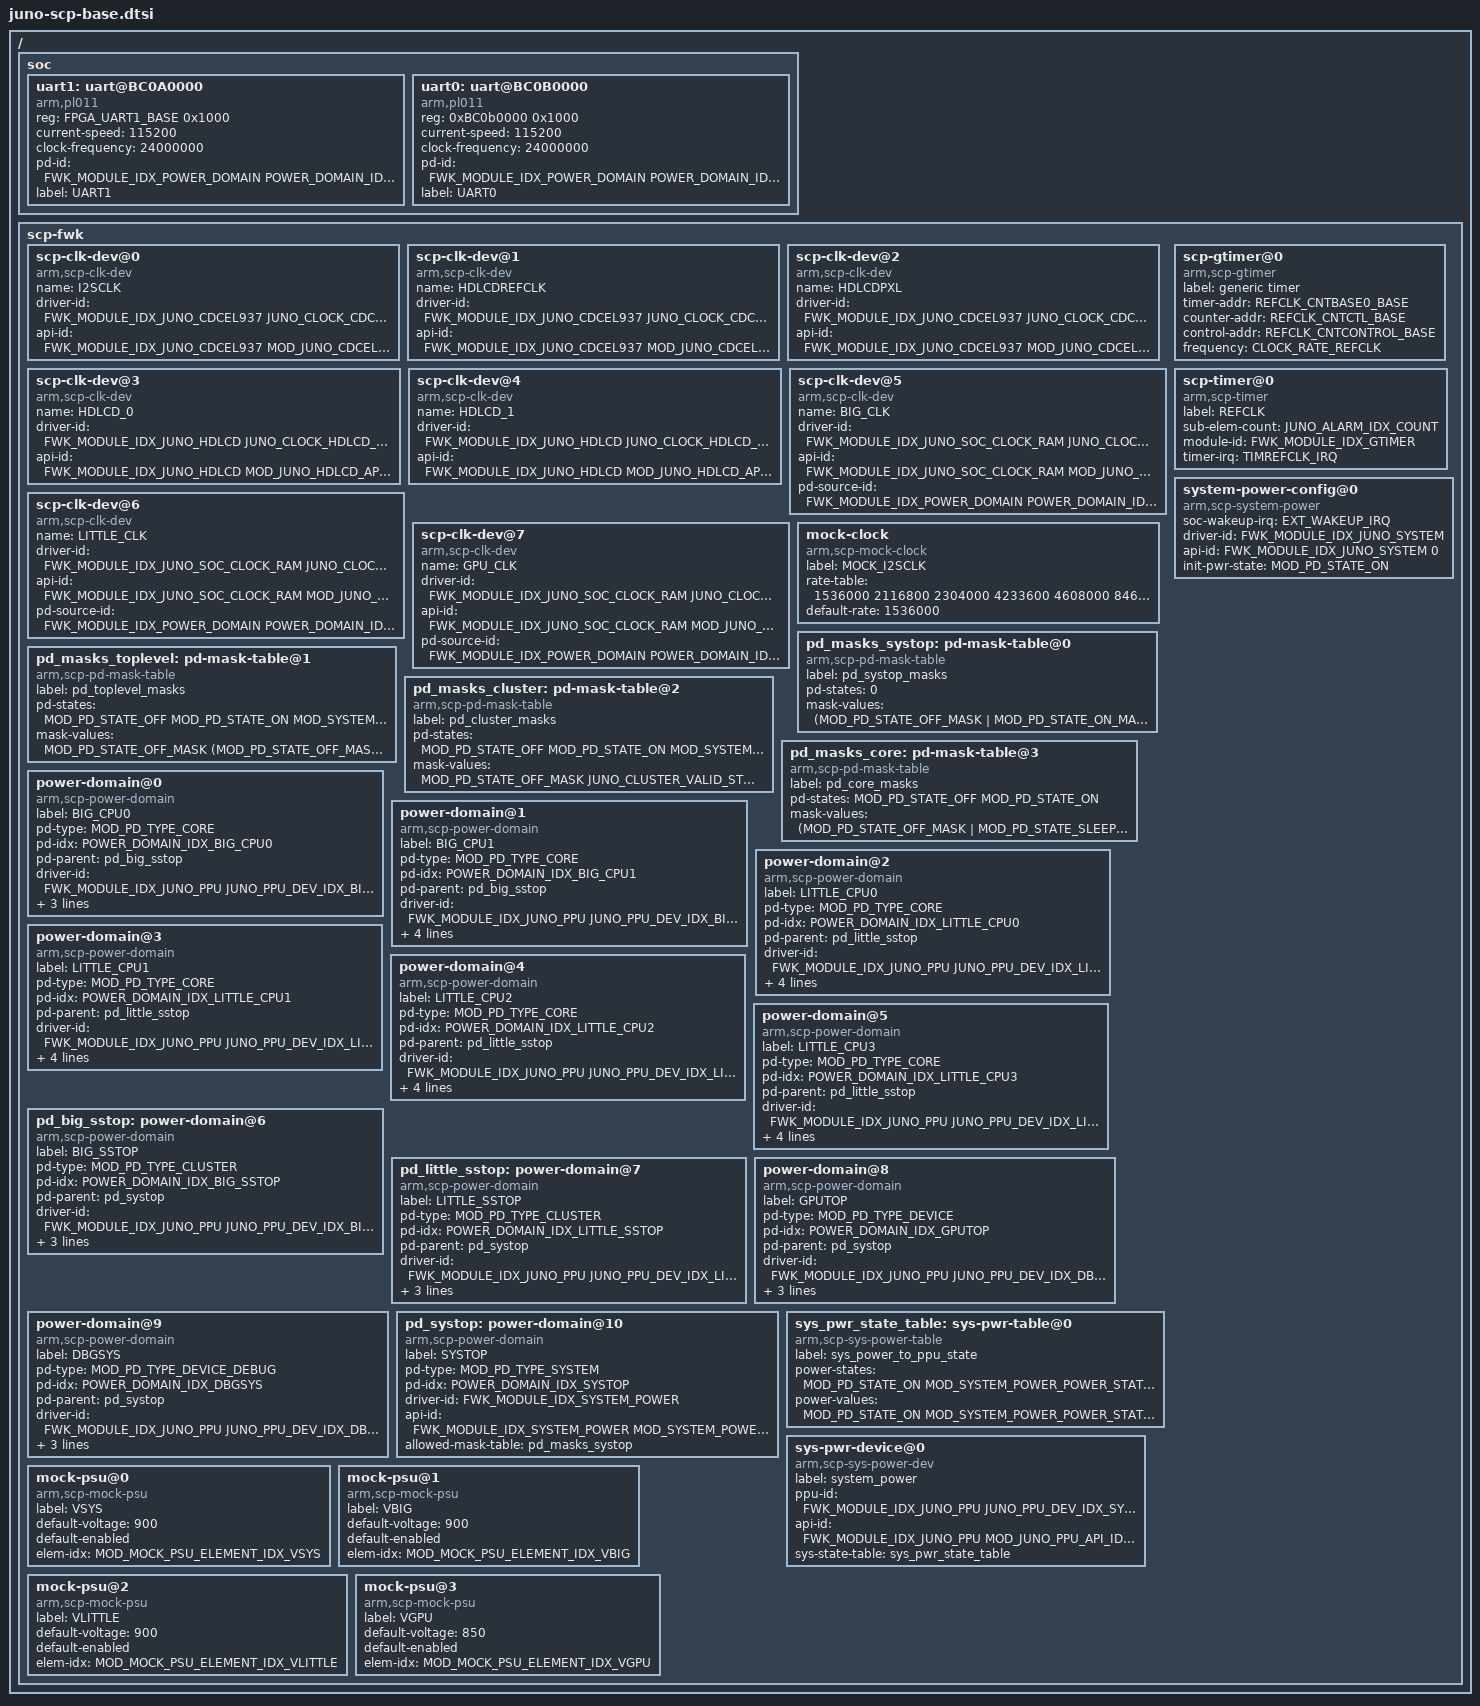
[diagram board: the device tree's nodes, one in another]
/*
 * Arm SCP/MCP Software
 * Copyright (c) 2021, Arm Limited and Contributors. All rights reserved.
 *
 * SPDX-License-Identifier: BSD-3-Clause
 */

/* base SCP .dtsi file for juno boards */

#include "fwk_dt_bindings.h"
#include "juno_dt_bindings.h"

/* must be first include */
#include "base.dtsi"



/ {
    soc {
	    #address-cells = <1>;
	    #size-cells = <1>;

        /* main console uart */
       	uart1: uart@BC0A0000 {
        	compatible = "arm,pl011";
			reg = <FPGA_UART1_BASE 0x1000>;
            current-speed = <115200>;
            clock-frequency = <24000000>;
            pd-id = <FWK_MODULE_IDX_POWER_DOMAIN POWER_DOMAIN_IDX_SYSTOP>;
/*			clocks = <&uartclk>;*/
/*			interrupts = <7 3>; */
/*			interrupt-names = "rx"; */
			label = "UART1";
	    };


/* another uart to validate generating arrays of elements */
        /* main console uart */
       	uart0: uart@BC0B0000 {
        	compatible = "arm,pl011";
			reg = <0xBC0b0000 0x1000>;
            current-speed = <115200>;
            clock-frequency = <24000000>;
            pd-id = <FWK_MODULE_IDX_POWER_DOMAIN POWER_DOMAIN_IDX_DBGSYS>;
/*			clocks = <&uartclk>;*/
/*			interrupts = <7 3>; */
/*			interrupt-names = "rx"; */
            label = "UART0";
	    };


    };

    scp-fwk {
        
        scp-clk-dev@0 {
            compatible = "arm,scp-clk-dev";
            name = "I2SCLK";
            driver-id = <FWK_MODULE_IDX_JUNO_CDCEL937 JUNO_CLOCK_CDCEL937_IDX_I2SCLK>;
            api-id = <FWK_MODULE_IDX_JUNO_CDCEL937 MOD_JUNO_CDCEL937_API_IDX_CLOCK_DRIVER>;            
        };

        scp-clk-dev@1 {
            compatible = "arm,scp-clk-dev";
            name = "HDLCDREFCLK";
            driver-id = <FWK_MODULE_IDX_JUNO_CDCEL937 JUNO_CLOCK_CDCEL937_IDX_HDLCDREFCLK>;
            api-id = <FWK_MODULE_IDX_JUNO_CDCEL937 MOD_JUNO_CDCEL937_API_IDX_CLOCK_DRIVER >;
        };

        scp-clk-dev@2 {
            compatible = "arm,scp-clk-dev";
            name = "HDLCDPXL";
            driver-id = <FWK_MODULE_IDX_JUNO_CDCEL937 JUNO_CLOCK_CDCEL937_IDX_HDLCDPXL>;
            api-id = <FWK_MODULE_IDX_JUNO_CDCEL937 MOD_JUNO_CDCEL937_API_IDX_CLOCK_DRIVER >;
        };

        scp-clk-dev@3 {
            compatible = "arm,scp-clk-dev";
            name = "HDLCD_0";
            driver-id = <FWK_MODULE_IDX_JUNO_HDLCD JUNO_CLOCK_HDLCD_IDX_HDLCD0>;
            api-id = <FWK_MODULE_IDX_JUNO_HDLCD MOD_JUNO_HDLCD_API_IDX_CLOCK_DRIVER>;
        };

        scp-clk-dev@4 {
            compatible = "arm,scp-clk-dev";
            name = "HDLCD_1";
            driver-id = <FWK_MODULE_IDX_JUNO_HDLCD JUNO_CLOCK_HDLCD_IDX_HDLCD1>;
            api-id = <FWK_MODULE_IDX_JUNO_HDLCD MOD_JUNO_HDLCD_API_IDX_CLOCK_DRIVER>;
        };

        scp-clk-dev@5 {
            compatible = "arm,scp-clk-dev";
            name = "BIG_CLK";
            driver-id = <FWK_MODULE_IDX_JUNO_SOC_CLOCK_RAM JUNO_CLOCK_SOC_RAM_IDX_BIGCLK>;
            api-id = <FWK_MODULE_IDX_JUNO_SOC_CLOCK_RAM MOD_JUNO_SOC_CLOCK_RAM_API_IDX_DRIVER>;
            pd-source-id = <FWK_MODULE_IDX_POWER_DOMAIN POWER_DOMAIN_IDX_BIG_SSTOP>;
        };

        scp-clk-dev@6 {
            compatible = "arm,scp-clk-dev";
            name = "LITTLE_CLK";
            driver-id = <FWK_MODULE_IDX_JUNO_SOC_CLOCK_RAM JUNO_CLOCK_SOC_RAM_IDX_LITTLECLK>;
            api-id = <FWK_MODULE_IDX_JUNO_SOC_CLOCK_RAM MOD_JUNO_SOC_CLOCK_RAM_API_IDX_DRIVER>;
            pd-source-id = <FWK_MODULE_IDX_POWER_DOMAIN POWER_DOMAIN_IDX_LITTLE_SSTOP>;
        };

        scp-clk-dev@7 {
            compatible = "arm,scp-clk-dev";
            name = "GPU_CLK";
            driver-id = <FWK_MODULE_IDX_JUNO_SOC_CLOCK_RAM JUNO_CLOCK_SOC_RAM_IDX_GPUCLK>;
            api-id = <FWK_MODULE_IDX_JUNO_SOC_CLOCK_RAM MOD_JUNO_SOC_CLOCK_RAM_API_IDX_DRIVER>;
            pd-source-id = <FWK_MODULE_IDX_POWER_DOMAIN POWER_DOMAIN_IDX_GPUTOP>;
        };

        mock-clock {
            compatible = "arm,scp-mock-clock";
            label = "MOCK_I2SCLK";
            rate-table = <1536000 2116800 2304000 4233600 4608000 8467200 9216000>;
            default-rate = <1536000>;
        };

        pd_masks_systop: pd-mask-table@0 {
            compatible = "arm,scp-pd-mask-table";
            label = "pd_systop_masks";
            pd-states = <0>;
            mask-values = <(MOD_PD_STATE_OFF_MASK | MOD_PD_STATE_ON_MASK | (1 << MOD_SYSTEM_POWER_POWER_STATE_SLEEP0))>;
        };

        pd_masks_toplevel: pd-mask-table@1 {
            compatible = "arm,scp-pd-mask-table";
            label = "pd_toplevel_masks";
            pd-states = <MOD_PD_STATE_OFF MOD_PD_STATE_ON MOD_SYSTEM_POWER_POWER_STATE_SLEEP0>;
            mask-values = <MOD_PD_STATE_OFF_MASK (MOD_PD_STATE_OFF_MASK | MOD_PD_STATE_ON_MASK) MOD_PD_STATE_OFF_MASK>;            
        };

        pd_masks_cluster: pd-mask-table@2 {
            compatible = "arm,scp-pd-mask-table";
            label = "pd_cluster_masks";
            pd-states = <MOD_PD_STATE_OFF MOD_PD_STATE_ON MOD_SYSTEM_POWER_POWER_STATE_SLEEP0>;
            mask-values = <MOD_PD_STATE_OFF_MASK JUNO_CLUSTER_VALID_STATE_MASK MOD_PD_STATE_OFF_MASK>;            
        };

        pd_masks_core: pd-mask-table@3 {
            compatible = "arm,scp-pd-mask-table";
            label = "pd_core_masks";
            pd-states = <MOD_PD_STATE_OFF MOD_PD_STATE_ON>;
            mask-values = <(MOD_PD_STATE_OFF_MASK | MOD_PD_STATE_SLEEP_MASK) JUNO_CORE_VALID_STATE_MASK>;
        };

        power-domain@0 {
            compatible = "arm,scp-power-domain";
            label = "BIG_CPU0";
            pd-type = <MOD_PD_TYPE_CORE>;
            pd-idx = <POWER_DOMAIN_IDX_BIG_CPU0>;
            pd-parent = <&pd_big_sstop>;
            driver-id = <FWK_MODULE_IDX_JUNO_PPU JUNO_PPU_DEV_IDX_BIG_CPU0>;
            api-id = <FWK_MODULE_IDX_JUNO_PPU MOD_JUNO_PPU_API_IDX_PD>;
            allowed-mask-table = <&pd_masks_core>;
        };

        power-domain@1 {
            compatible = "arm,scp-power-domain";
            label = "BIG_CPU1";
            pd-type = <MOD_PD_TYPE_CORE>;
            pd-idx = <POWER_DOMAIN_IDX_BIG_CPU1>;
            pd-parent = <&pd_big_sstop>;
            driver-id = <FWK_MODULE_IDX_JUNO_PPU JUNO_PPU_DEV_IDX_BIG_CPU1>;
            api-id = <FWK_MODULE_IDX_JUNO_PPU MOD_JUNO_PPU_API_IDX_PD>;
            allowed-mask-table = <&pd_masks_core>;
            disable-state-trans-notifications;
        };

        power-domain@2 {
            compatible = "arm,scp-power-domain";
            label = "LITTLE_CPU0";
            pd-type = <MOD_PD_TYPE_CORE>;
            pd-idx = <POWER_DOMAIN_IDX_LITTLE_CPU0>;
            pd-parent = <&pd_little_sstop>;
            driver-id = <FWK_MODULE_IDX_JUNO_PPU JUNO_PPU_DEV_IDX_LITTLE_CPU0>;
            api-id = <FWK_MODULE_IDX_JUNO_PPU MOD_JUNO_PPU_API_IDX_PD>;
            allowed-mask-table = <&pd_masks_core>;
            disable-state-trans-notifications;
        };

        power-domain@3 {
            compatible = "arm,scp-power-domain";
            label = "LITTLE_CPU1";
            pd-type = <MOD_PD_TYPE_CORE>;
            pd-idx = <POWER_DOMAIN_IDX_LITTLE_CPU1>;
            pd-parent = <&pd_little_sstop>;
            driver-id = <FWK_MODULE_IDX_JUNO_PPU JUNO_PPU_DEV_IDX_LITTLE_CPU1>;
            api-id = <FWK_MODULE_IDX_JUNO_PPU MOD_JUNO_PPU_API_IDX_PD>;
            allowed-mask-table = <&pd_masks_core>;
            disable-state-trans-notifications;
        };
        
        power-domain@4 {
            compatible = "arm,scp-power-domain";
            label = "LITTLE_CPU2";
            pd-type = <MOD_PD_TYPE_CORE>;
            pd-idx = <POWER_DOMAIN_IDX_LITTLE_CPU2>;
            pd-parent = <&pd_little_sstop>;
            driver-id = <FWK_MODULE_IDX_JUNO_PPU JUNO_PPU_DEV_IDX_LITTLE_CPU2>;
            api-id = <FWK_MODULE_IDX_JUNO_PPU MOD_JUNO_PPU_API_IDX_PD>;
            allowed-mask-table = <&pd_masks_core>;
            disable-state-trans-notifications;
        };
        
        power-domain@5 {
            compatible = "arm,scp-power-domain";
            label = "LITTLE_CPU3";
            pd-type = <MOD_PD_TYPE_CORE>;
            pd-idx = <POWER_DOMAIN_IDX_LITTLE_CPU3>;
            pd-parent = <&pd_little_sstop>;
            driver-id = <FWK_MODULE_IDX_JUNO_PPU JUNO_PPU_DEV_IDX_LITTLE_CPU3>;
            api-id = <FWK_MODULE_IDX_JUNO_PPU MOD_JUNO_PPU_API_IDX_PD>;
            allowed-mask-table = <&pd_masks_core>;
            disable-state-trans-notifications;
        };

        pd_big_sstop: power-domain@6 {
            compatible = "arm,scp-power-domain";
            label = "BIG_SSTOP";
            pd-type = <MOD_PD_TYPE_CLUSTER>;
            pd-idx = <POWER_DOMAIN_IDX_BIG_SSTOP>;
            pd-parent = <&pd_systop>;
            driver-id = <FWK_MODULE_IDX_JUNO_PPU JUNO_PPU_DEV_IDX_BIG_SSTOP>;
            api-id = <FWK_MODULE_IDX_SYSTEM_POWER MOD_SYSTEM_POWER_API_IDX_PD_DRIVER>;
            allowed-mask-table = <&pd_masks_cluster>;
        };

        pd_little_sstop: power-domain@7 {
            compatible = "arm,scp-power-domain";
            label = "LITTLE_SSTOP";
            pd-type = <MOD_PD_TYPE_CLUSTER>;
            pd-idx = <POWER_DOMAIN_IDX_LITTLE_SSTOP>;
            pd-parent = <&pd_systop>;
            driver-id = <FWK_MODULE_IDX_JUNO_PPU JUNO_PPU_DEV_IDX_LITTLE_SSTOP>;
            api-id = <FWK_MODULE_IDX_SYSTEM_POWER MOD_SYSTEM_POWER_API_IDX_PD_DRIVER>;
            allowed-mask-table = <&pd_masks_cluster>;
        };

        power-domain@8 {
            compatible = "arm,scp-power-domain";
            label = "GPUTOP";
            pd-type = <MOD_PD_TYPE_DEVICE>;
            pd-idx = <POWER_DOMAIN_IDX_GPUTOP>;
            pd-parent = <&pd_systop>;
            driver-id = <FWK_MODULE_IDX_JUNO_PPU JUNO_PPU_DEV_IDX_DBGSYS>;
            api-id = <FWK_MODULE_IDX_SYSTEM_POWER MOD_SYSTEM_POWER_API_IDX_PD_DRIVER>;
            allowed-mask-table = <&pd_masks_toplevel>;
        };

        power-domain@9 {
            compatible = "arm,scp-power-domain";
            label = "DBGSYS";
            pd-type = <MOD_PD_TYPE_DEVICE_DEBUG>;
            pd-idx = <POWER_DOMAIN_IDX_DBGSYS>;
            pd-parent = <&pd_systop>;
            driver-id = <FWK_MODULE_IDX_JUNO_PPU JUNO_PPU_DEV_IDX_DBGSYS>;
            api-id = <FWK_MODULE_IDX_SYSTEM_POWER MOD_SYSTEM_POWER_API_IDX_PD_DRIVER>;
            allowed-mask-table = <&pd_masks_toplevel>;
        };

        pd_systop: power-domain@10 {
            compatible = "arm,scp-power-domain";
            label = "SYSTOP";
            pd-type = <MOD_PD_TYPE_SYSTEM>;
            pd-idx = <POWER_DOMAIN_IDX_SYSTOP>;
            driver-id = <FWK_MODULE_IDX_SYSTEM_POWER>;
            api-id = <FWK_MODULE_IDX_SYSTEM_POWER MOD_SYSTEM_POWER_API_IDX_PD_DRIVER>;
            allowed-mask-table = <&pd_masks_systop>;
        };

        scp-gtimer@0 {
            compatible = "arm,scp-gtimer";
            label = "generic timer";
            timer-addr = <REFCLK_CNTBASE0_BASE>;
            counter-addr = <REFCLK_CNTCTL_BASE>;
            control-addr = <REFCLK_CNTCONTROL_BASE>;
            frequency = <CLOCK_RATE_REFCLK>;            
        };

        scp-timer@0 {
            compatible = "arm,scp-timer";
            label = "REFCLK";
            sub-elem-count = <JUNO_ALARM_IDX_COUNT>;
            module-id = <FWK_MODULE_IDX_GTIMER>;
            timer-irq = <TIMREFCLK_IRQ>;
        };

        sys_pwr_state_table: sys-pwr-table@0 {
            compatible = "arm,scp-sys-power-table";
            label = "sys_power_to_ppu_state";
            power-states = <MOD_PD_STATE_ON MOD_SYSTEM_POWER_POWER_STATE_SLEEP0 MOD_PD_STATE_OFF>;
            power-values = <MOD_PD_STATE_ON MOD_SYSTEM_POWER_POWER_STATE_SLEEP0 MOD_PD_STATE_OFF>;
        };

        sys-pwr-device@0 {
            compatible = "arm,scp-sys-power-dev";
            label = "system_power";
            ppu-id = <FWK_MODULE_IDX_JUNO_PPU JUNO_PPU_DEV_IDX_SYSTOP>;
            api-id = <FWK_MODULE_IDX_JUNO_PPU MOD_JUNO_PPU_API_IDX_PD>;
            sys-state-table = <&sys_pwr_state_table>;
        };

        system-power-config@0 {
            compatible = "arm,scp-system-power";
            soc-wakeup-irq = <EXT_WAKEUP_IRQ>;
            driver-id = <FWK_MODULE_IDX_JUNO_SYSTEM>;
            api-id = <FWK_MODULE_IDX_JUNO_SYSTEM 0>;
            init-pwr-state = <MOD_PD_STATE_ON>;

        };

        mock-psu@0 {
            compatible = "arm,scp-mock-psu";
            label = "VSYS";
            default-voltage = <900>;
            default-enabled;
            elem-idx = <MOD_MOCK_PSU_ELEMENT_IDX_VSYS>;            
        };

       mock-psu@1 {
            compatible = "arm,scp-mock-psu";
            label = "VBIG";
            default-voltage = <900>;
            default-enabled;
            elem-idx = <MOD_MOCK_PSU_ELEMENT_IDX_VBIG>;            
        };

        mock-psu@2 {
            compatible = "arm,scp-mock-psu";
            label = "VLITTLE";
            default-voltage = <900>;
            default-enabled;
            elem-idx = <MOD_MOCK_PSU_ELEMENT_IDX_VLITTLE>;            
        };

        mock-psu@3 {
            compatible = "arm,scp-mock-psu";
            label = "VGPU";
            default-voltage = <850>;
            default-enabled;
            elem-idx = <MOD_MOCK_PSU_ELEMENT_IDX_VGPU>;            
        };

    };
};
